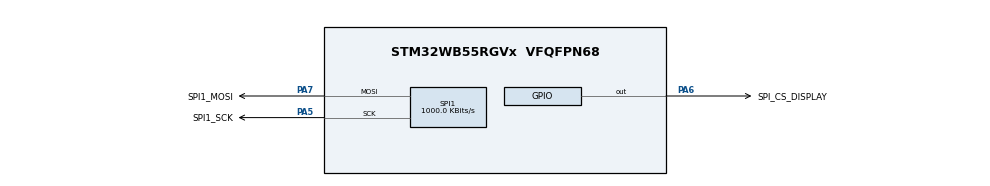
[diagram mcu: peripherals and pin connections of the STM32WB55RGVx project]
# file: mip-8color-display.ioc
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Mcu.Family=STM32WB
Mcu.Name=STM32WB55RGVx
Mcu.Package=VFQFPN68
NVIC.PriorityGroup=NVIC_PRIORITYGROUP_4
PA5.GPIO_Label=SPI1_SCK
PA5.GPIO_PuPd=GPIO_PULLDOWN
PA5.GPIO_Speed=GPIO_SPEED_FREQ_MEDIUM
PA5.Mode=TX_Only_Simplex_Unidirect_Master
PA5.Signal=SPI1_SCK
PA6.GPIO_Label=SPI_CS_DISPLAY
PA6.GPIO_Speed=GPIO_SPEED_FREQ_MEDIUM
PA6.Signal=GPIO_Output
PA7.GPIO_Label=SPI1_MOSI
PA7.GPIO_Speed=GPIO_SPEED_FREQ_MEDIUM
PA7.Mode=TX_Only_Simplex_Unidirect_Master
PA7.Signal=SPI1_MOSI
ProjectManager.HeapSize=0x200
ProjectManager.StackSize=0x400
ProjectManager.TargetToolchain=CMake
RCC.ADCFreq_Value=128000000
RCC.AHBFreq_Value=32000000
RCC.APB1Freq_Value=32000000
RCC.APB1TimFreq_Value=32000000
RCC.APB2Freq_Value=32000000
RCC.APB2TimFreq_Value=32000000
RCC.APB3Freq_Value=16000000
RCC.CortexFreq_Value=32000000
RCC.HCLKFreq_Value=32000000
RCC.HSE_VALUE=8000000
RCC.HSI48_VALUE=48000000
RCC.HSI_VALUE=16000000
RCC.LSE_VALUE=32768
RCC.MSIClockRange=RCC_MSIRANGE_10
RCC.SYSCLKFreq_VALUE=32000000
RCC.USBFreq_Value=128000000
RCC.VCOOutputFreq_Value=256000000
SPI1.BaudRatePrescaler=SPI_BAUDRATEPRESCALER_32
SPI1.CalculateBaudRate=1000.0 KBits/s
SPI1.DataSize=SPI_DATASIZE_8BIT
SPI1.Direction=SPI_DIRECTION_2LINES
SPI1.Mode=SPI_MODE_MASTER
SPI1.VirtualType=VM_MASTER
TIM2.Prescaler=64-1
VP_MEMORYMAP_VS_MEMORYMAP.Mode=CurAppReg
VP_TIM2_VS_ClockSourceINT.Mode=Internal
board=custom

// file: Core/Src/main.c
/* USER CODE BEGIN Header */
/**
  ******************************************************************************
  * @file           : main.c
  * @brief          : Main program body
  ******************************************************************************
  * @attention
  *
  * Copyright (c) 2026 STMicroelectronics.
  * All rights reserved.
  *
  * This software is licensed under terms that can be found in the LICENSE file
  * in the root directory of this software component.
  * If no LICENSE file comes with this software, it is provided AS-IS.
  *
  ******************************************************************************
  */
/* USER CODE END Header */
#include "main.h"
#include "graphics/gfx_font.h"
#include "spi.h"
#include "stm32wbxx_hal_tim.h"
#include "tim.h"
#include "gpio.h"

/* USER CODE BEGIN Includes */
#include "MIP-8c/mip-8c-display.h"
#include "MIP-8c/graphics/gfx_icons.h"
#include "stm32wbxx_hal.h"
#include <stdint.h>
/* USER CODE END Includes */

void SystemClock_Config(void);
void PeriphCommonClock_Config(void);

int main(void)
{

  /* MCU Configuration--------------------------------------------------------*/

  /* Reset of all peripherals, Initializes the Flash interface and the Systick. */
  HAL_Init();

  /* Configure the system clock */
  SystemClock_Config();

  /* Configure the peripherals common clocks */
  PeriphCommonClock_Config();

  /* Initialize all configured peripherals */
  MX_GPIO_Init();
  MX_SPI1_Init();
  MX_TIM2_Init();
  /* USER CODE BEGIN 2 */

  HAL_TIM_Base_Start(&htim2);

  HAL_Delay(1000);

  MIP_8c_Display_Config_t display_config =
  {
    .hspi = &hspi1,
    .cs_port = SPI_CS_DISPLAY_GPIO_Port,
    .cs_pin = SPI_CS_DISPLAY_Pin
  };
  MIP_8c_Display_Init(&display_config);
  HAL_Delay(100);

  // Clear all screen
  for(int i = 0; i < SCREEN_HEIGHT_IN_PIXELS; i++)
  {
    MIP_8c_Display_DrawHorizontalLine(i, JDI_8COL_BLACK);
  }
  MIP_8c_Display_RefreshScreen(0, SCREEN_HEIGHT_IN_PIXELS);
  HAL_Delay(500);

  // Clear all screen
  for(int i = 0; i < SCREEN_HEIGHT_IN_PIXELS; i++)
  {
    MIP_8c_Display_DrawHorizontalLine(i, JDI_8COL_WHITE);
  }
  MIP_8c_Display_RefreshScreen(0, SCREEN_HEIGHT_IN_PIXELS);
  HAL_Delay(500);

  uint8_t color = JDI_8COL_CYAN;
  uint32_t start = __HAL_TIM_GET_COUNTER(&htim2);

  color = JDI_8COL_BLACK;
  MIP_8c_Display_DrawText(1, 5, color, &gfx_font_bitmap_robo_cond_l, "|dA1.9876");
  MIP_8c_Display_DrawText(1, 80, color, &gfx_font_bitmap_robo_cond_m, "|dA1.9876");
  MIP_8c_Display_DrawText(1, 125, color, &gfx_font_bitmap_robo_cond_s, "|dA1.9876");
  // MIP_8c_Display_DrawText(1, 40, color, &gfx_font_bitmap_robo_cond_s, "ABCDEFGH");
  // MIP_8c_Display_DrawText(1, 75, color, &gfx_font_bitmap_robo_cond_m, "abcdefgh");
  // // MIP_8c_Display_DrawText(1, 110, color, &gfx_font_bitmap_robo_cond_s, "!@#$\%^&");
  // MIP_8c_Display_DrawText(1, 145, color, &gfx_font_bitmap_robo_cond_m, "{}[]|,.");

  uint32_t stop = __HAL_TIM_GET_COUNTER(&htim2);
  uint32_t delta = stop - start;

  MIP_8c_Display_RefreshScreen(0, SCREEN_HEIGHT_IN_PIXELS);

  /* USER CODE END 2 */

  /* Infinite loop */
  while (1)
  {

  }
}

void SystemClock_Config(void)
{
  RCC_OscInitTypeDef RCC_OscInitStruct = {0};
  RCC_ClkInitTypeDef RCC_ClkInitStruct = {0};

  /** Configure the main internal regulator output voltage
  */
  __HAL_PWR_VOLTAGESCALING_CONFIG(PWR_REGULATOR_VOLTAGE_SCALE1);

  /** Initializes the RCC Oscillators according to the specified parameters
  * in the RCC_OscInitTypeDef structure.
  */
  RCC_OscInitStruct.OscillatorType = RCC_OSCILLATORTYPE_HSI|RCC_OSCILLATORTYPE_MSI;
  RCC_OscInitStruct.HSIState = RCC_HSI_ON;
  RCC_OscInitStruct.MSIState = RCC_MSI_ON;
  RCC_OscInitStruct.HSICalibrationValue = RCC_HSICALIBRATION_DEFAULT;
  RCC_OscInitStruct.MSICalibrationValue = RCC_MSICALIBRATION_DEFAULT;
  RCC_OscInitStruct.MSIClockRange = RCC_MSIRANGE_10;
  RCC_OscInitStruct.PLL.PLLState = RCC_PLL_NONE;
  if (HAL_RCC_OscConfig(&RCC_OscInitStruct) != HAL_OK)
  {
    Error_Handler();
  }

  /** Configure the SYSCLKSource, HCLK, PCLK1 and PCLK2 clocks dividers
  */
  RCC_ClkInitStruct.ClockType = RCC_CLOCKTYPE_HCLK4|RCC_CLOCKTYPE_HCLK2
                              |RCC_CLOCKTYPE_HCLK|RCC_CLOCKTYPE_SYSCLK
                              |RCC_CLOCKTYPE_PCLK1|RCC_CLOCKTYPE_PCLK2;
  RCC_ClkInitStruct.SYSCLKSource = RCC_SYSCLKSOURCE_MSI;
  RCC_ClkInitStruct.AHBCLKDivider = RCC_SYSCLK_DIV1;
  RCC_ClkInitStruct.APB1CLKDivider = RCC_HCLK_DIV1;
  RCC_ClkInitStruct.APB2CLKDivider = RCC_HCLK_DIV1;
  RCC_ClkInitStruct.AHBCLK2Divider = RCC_SYSCLK_DIV1;
  RCC_ClkInitStruct.AHBCLK4Divider = RCC_SYSCLK_DIV1;

  if (HAL_RCC_ClockConfig(&RCC_ClkInitStruct, FLASH_LATENCY_1) != HAL_OK)
  {
    Error_Handler();
  }
}

void PeriphCommonClock_Config(void)
{
  RCC_PeriphCLKInitTypeDef PeriphClkInitStruct = {0};

  /** Initializes the peripherals clock
  */
  PeriphClkInitStruct.PeriphClockSelection = RCC_PERIPHCLK_SMPS;
  PeriphClkInitStruct.SmpsClockSelection = RCC_SMPSCLKSOURCE_HSI;
  PeriphClkInitStruct.SmpsDivSelection = RCC_SMPSCLKDIV_RANGE1;

  if (HAL_RCCEx_PeriphCLKConfig(&PeriphClkInitStruct) != HAL_OK)
  {
    Error_Handler();
  }
}

void Error_Handler(void)
{
  __disable_irq();
  while (1)
  {
  }
}
